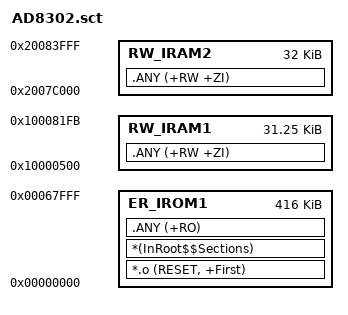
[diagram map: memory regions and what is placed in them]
; *************************************************************
; *** Scatter-Loading Description File generated by uVision ***
; *************************************************************

LR_IROM1 0x00000000 0x00068000  {    ; load region size_region
  ER_IROM1 0x00000000 0x00068000  {  ; load address = execution address
   *.o (RESET, +First)
   *(InRoot$$Sections)
   .ANY (+RO)
  }
  RW_IRAM1 0x10000500 0x00007CFC  {  ; RW data
   .ANY (+RW +ZI)
  }
  RW_IRAM2 0x2007C000 0x00008000  {
   .ANY (+RW +ZI)
  }
}

